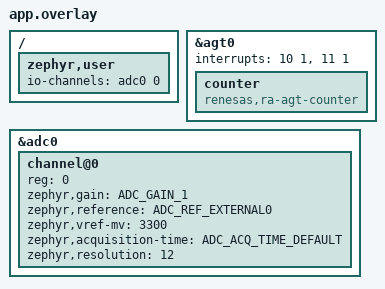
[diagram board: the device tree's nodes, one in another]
&agt0  	{
	interrupts = <10 1>, <11 1>;
	interrupt-names = "agti", "agtcmai";
	status = "okay";

	counter {
		compatible = "renesas,ra-agt-counter";
		status = "okay";
	};
};


/ {
    zephyr,user {
        io-channels = <&adc0 0>;
    };
};

&adc0 {

    #address-cells = <1>;
    #size-cells = <0>;

    channel@0 {
        reg = <0>;
        zephyr,gain = "ADC_GAIN_1";
        zephyr,reference = "ADC_REF_EXTERNAL0";
        zephyr,vref-mv = <3300>;
        zephyr,acquisition-time = <ADC_ACQ_TIME_DEFAULT>;
        zephyr,resolution = <12>;
    };
};
